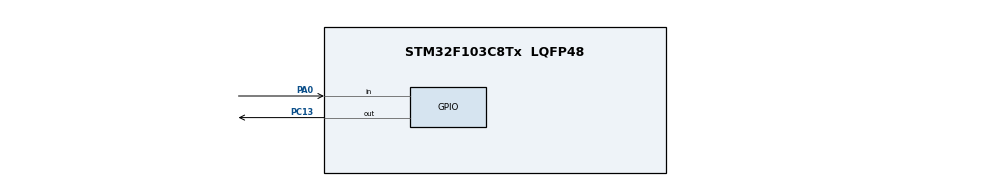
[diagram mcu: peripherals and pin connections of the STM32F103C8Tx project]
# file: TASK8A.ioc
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Mcu.Family=STM32F1
Mcu.Name=STM32F103C8Tx
Mcu.Package=LQFP48
PA0.Signal=GPIO_Input
PA0.GPIO_PuPd=GPIO_PULLUP
PA13.Mode=Serial_Wire
PA13.Signal=SYS_JTMS-SWDIO
PA14.Mode=Serial_Wire
PA14.Signal=SYS_JTCK-SWCLK
PC13.Signal=GPIO_Output
PC13.GPIO_Output_Level=GPIO_PIN_SET
ProjectManager.TargetToolchain=MDK-ARM V5.32
RCC.AHBFreq_Value=72000000
RCC.APB1Freq_Value=36000000
RCC.APB2Freq_Value=72000000
RCC.CortexFreq_Value=72000000
RCC.HCLKFreq_Value=72000000
RCC.SYSCLKFreq_VALUE=72000000
RCC.SYSCLKSource=RCC_SYSCLKSOURCE_PLLCLK
board=custom

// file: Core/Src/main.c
/* USER CODE BEGIN Header */
/**
  ******************************************************************************
  * @file           : main.c
  * @brief          : CAT 8 - TASK 8A: GPIO Direct Follow Mode
  * Target Device   : STM32F103C8T6 (STM32 Blue Pill, ARM Cortex-M3 @ 72 MHz)
  * Pin Map         : PA0  -> Push-Button input (Active-LOW with Internal Pull-up)
  *                   PC13 -> Onboard LED output (Active-LOW)
  ******************************************************************************
  */
/* USER CODE END Header */
#include "main.h"

/* USER CODE BEGIN Includes */
#include <stdbool.h>
/* USER CODE END Includes */

void SystemClock_Config(void);
static void MX_GPIO_Init(void);

int main(void)
{

  /* MCU Configuration--------------------------------------------------------*/

  /* Reset of all peripherals, Initializes the Flash interface and the Systick. */
  HAL_Init();

  /* Configure the system clock */
  SystemClock_Config();

  /* Initialize all configured peripherals */
  MX_GPIO_Init();
  /* USER CODE BEGIN 2 */
  /* Ensure LED is initially OFF (Active-LOW PC13 is HIGH) */
  HAL_GPIO_WritePin(GPIOC, GPIO_PIN_13, GPIO_PIN_SET);
  /* USER CODE END 2 */

  /* Infinite loop */
  /* USER CODE BEGIN WHILE */
  while (1)
  {
    /* Direct Follow Mode: Button Pressed (LOW) -> LED ON (LOW) */
    if (HAL_GPIO_ReadPin(GPIOA, GPIO_PIN_0) == GPIO_PIN_RESET)
    {
      HAL_GPIO_WritePin(GPIOC, GPIO_PIN_13, GPIO_PIN_RESET); /* LED ON */
    }
    else
    {
      HAL_GPIO_WritePin(GPIOC, GPIO_PIN_13, GPIO_PIN_SET);   /* LED OFF */
    }
    /* USER CODE END WHILE */

  }
}

void SystemClock_Config(void)
{
  RCC_OscInitTypeDef RCC_OscInitStruct = {0};
  RCC_ClkInitTypeDef RCC_ClkInitStruct = {0};

  RCC_OscInitStruct.OscillatorType = RCC_OSCILLATORTYPE_HSE;
  RCC_OscInitStruct.HSEState = RCC_HSE_ON;
  RCC_OscInitStruct.HSEPredivValue = RCC_HSE_PREDIV_DIV1;
  RCC_OscInitStruct.HSIState = RCC_HSI_ON;
  RCC_OscInitStruct.PLL.PLLState = RCC_PLL_ON;
  RCC_OscInitStruct.PLL.PLLSource = RCC_PLLSOURCE_HSE;
  RCC_OscInitStruct.PLL.PLLMUL = RCC_PLL_MUL9;
  if (HAL_RCC_OscConfig(&RCC_OscInitStruct) != HAL_OK)
  {
    Error_Handler();
  }

  RCC_ClkInitStruct.ClockType = RCC_CLOCKTYPE_HCLK|RCC_CLOCKTYPE_SYSCLK
                              |RCC_CLOCKTYPE_PCLK1|RCC_CLOCKTYPE_PCLK2;
  RCC_ClkInitStruct.SYSCLKSource = RCC_SYSCLKSOURCE_PLLCLK;
  RCC_ClkInitStruct.AHBCLKDivider = RCC_SYSCLK_DIV1;
  RCC_ClkInitStruct.APB1CLKDivider = RCC_HCLK_DIV2;
  RCC_ClkInitStruct.APB2CLKDivider = RCC_HCLK_DIV1;

  if (HAL_RCC_ClockConfig(&RCC_ClkInitStruct, FLASH_LATENCY_2) != HAL_OK)
  {
    Error_Handler();
  }
}

static void MX_GPIO_Init(void)
{
  GPIO_InitTypeDef GPIO_InitStruct = {0};

  /* GPIO Ports Clock Enable */
  __HAL_RCC_GPIOC_CLK_ENABLE();
  __HAL_RCC_GPIOD_CLK_ENABLE();
  __HAL_RCC_GPIOA_CLK_ENABLE();

  /* Configure GPIO pin Output Level */
  HAL_GPIO_WritePin(GPIOC, GPIO_PIN_13, GPIO_PIN_SET);

  /* Configure GPIO pin : PC13 (Onboard LED) */
  GPIO_InitStruct.Pin = GPIO_PIN_13;
  GPIO_InitStruct.Mode = GPIO_MODE_OUTPUT_OD;
  GPIO_InitStruct.Pull = GPIO_NOPULL;
  GPIO_InitStruct.Speed = GPIO_SPEED_FREQ_LOW;
  HAL_GPIO_Init(GPIOC, &GPIO_InitStruct);

  /* Configure GPIO pin : PA0 (Push Button with Internal Pull-Up) */
  GPIO_InitStruct.Pin = GPIO_PIN_0;
  GPIO_InitStruct.Mode = GPIO_MODE_INPUT;
  GPIO_InitStruct.Pull = GPIO_PULLUP;
  HAL_GPIO_Init(GPIOA, &GPIO_InitStruct);
}

void Error_Handler(void)
{
  __disable_irq();
  while (1)
  {
  }
}
